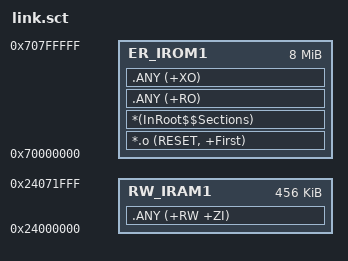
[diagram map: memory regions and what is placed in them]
; *************************************************************
; *** Scatter-Loading Description File generated by uVision ***
; *************************************************************

LR_IROM1 0x70000000 0x00800000  {    ; load region size_region
  ER_IROM1 0x70000000 0x00800000  {  ; load address = execution address
   *.o (RESET, +First)
   *(InRoot$$Sections)
   .ANY (+RO)
   .ANY (+XO)
  }
  RW_IRAM1 0x24000000 0x00072000  {  ; AXI SRAM MAXIM 456K
   .ANY (+RW +ZI)
  }
}


